# USBTLL register map
Vendor: Texas Instruments
Peripheral module from a debugger description file (folder omap34xx).
Registers are 8-bit, access per field, reset values left out (the file's numbers can be read two ways) unless marked. A register's access mark holds for its fields unless they carry their own. Offsets are as the file gives them; lines under a group give offsets from that group; [hi:lo] are bit positions; {n}, {i} and the like mark numbered series; 'fields as' and 'values as' point back to an identical list; <NAME> marks a mode.

## USBTLL
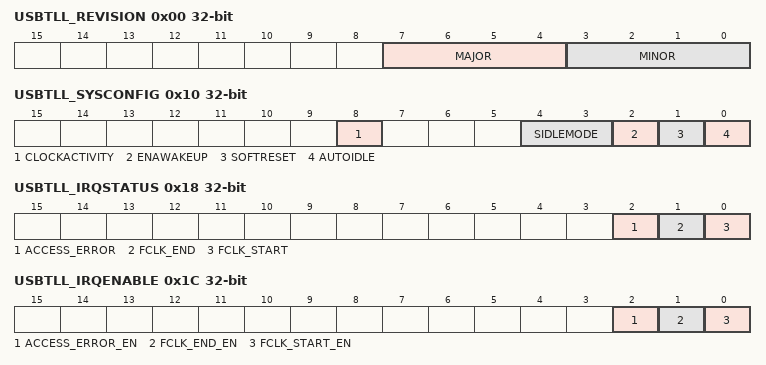
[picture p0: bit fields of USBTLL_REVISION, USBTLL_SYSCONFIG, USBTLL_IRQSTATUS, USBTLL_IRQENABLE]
0x00 USBTLL_REVISION 32-bit ro — Standard revision number, BCD encoded
  [7:4] MAJOR — Major revision number
  [3:0] MINOR — Minor revision number
0x10 USBTLL_SYSCONFIG 32-bit — Standard system configuration register
  [8] CLOCKACTIVITY rw — Enable autogating of L3 interconnect-derived internal clocks while module is idle.
    0=L3 interconnect-derived internal clocks OFF during idle; 1=L3 interconnect-derived internal clocks ON during idle
  [4:3] SIDLEMODE rw — Slave interface power management control. Idle Req/ack control
    0=Force-Idle mode. Sidleack asserted after Idlereq assertion; 1=No-idle mode. Sidleack never asserted.; 2=Smart-idle mode. Sidleack asserted after Idlereq assertion when no more activity on the USB.
  [2] ENAWAKEUP rw — Asynchronous wakeup generation control (Swakeup)
    0=Wakeup generation disabled; 1=Wakeup generation enabled
  [1] SOFTRESET wo — Module software reset
    0=No effect; 1=Starts softreset sequence
  [0] AUTOIDLE rw — Internal autogating control
    0=Clock always running; 1=When no activity on L3 interconnect, clock is cut off
0x14 USBTLL_SYSSTATUS 32-bit ro — Standard system status register
  [0] RESETDONE — Indicates when the module has entirely come out of reset
    0=Reset is ongoing; 1=Reset is done
0x18 USBTLL_IRQSTATUS 32-bit — Standard IRQ status vector. Write 1 to clear a bit.
  [all] fields
    0=No event pending; 1=Event pending
  [2] ACCESS_ERROR rw — Access error to ULPI register over L3 interconnect: USB clock must run for that type of access to succeed.
  [1] FCLK_END rw — Functional clock is no longer requested for USB clockingWhen TLL_SHARED_CONF[1] FCLK_REQ=0 and TLL_SHARED_CONF[0] FCLK_IS_ON=1, IRQ is generated to request the clock to be switched OFF and FCLK_END is set to 1.
  [0] FCLK_START rw — Functional clock is requested for USB clockingWhen TLL_SHARED_CONF[1] FCLK_REQ=1 and TLL_SHARED_CONF[0] FCLK_IS_ON=0, IRQ is generated to request the clock to be switched ON and FCLK_START is set to 1.
0x1C USBTLL_IRQENABLE 32-bit — Standard IRQ enable vector
  [all] fields
    0=IRQ event is masked; 1=IRQ event is enabled
  [2] ACCESS_ERROR_EN rw — Enable IRQ generation upon access error to ULPI register over L3 interconnect
  [1] FCLK_END_EN rw — IRQ event mask for FCLK_END interrupt (seeUSBTLL_IRQSTATUS[1])
  [0] FCLK_START_EN rw — IRQ event mask for FCLK_START interrupt (seeUSBTLL_IRQSTATUS[0])
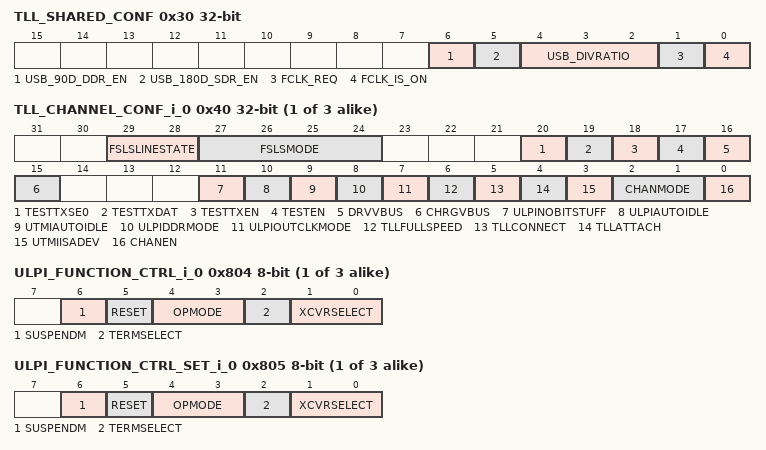
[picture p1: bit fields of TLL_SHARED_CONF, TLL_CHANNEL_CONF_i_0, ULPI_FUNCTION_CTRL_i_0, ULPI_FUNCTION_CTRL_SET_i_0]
0x30 TLL_SHARED_CONF 32-bit — Common control register for all TLL channels
  [6] USB_90D_DDR_EN rw — Software enable/disable of the 90-degree phase shift scheme on output DDR data, when implemented. Read-only, always-0 when HDL generic ULPI_90DEG4DDR = 0.
    0=ULPI DDR output DATA aligned with CLK; 1=ULPI DDR output DATA delayed by 90 degree wrt CLK
  [5] USB_180D_SDR_EN rw — Software enable/disable of the 180-degree phase shift scheme on output SDR data, when implemented. Read-only, always-0 when HDL generic ULPI_180DEG4SDR = 0
    0=ULPI SDR output DATA aligned with CLK; 1=ULPI SDR output DATA delayed by 180 degree wrt CLK
  [4:2] USB_DIVRATIO rw — (Log2 of) division ratio from functional clock to USB (UTMI/ULPI) clock
    0=Div ratio is 2**0 = 1 : Bypass; 1=Div ratio is 2**1 = 2; 2=Div ratio is 2**2 = 4; 3=Div ratio is 2**3 = 8; 4=Div ratio is 2**4 = 16; 5=Div ratio is 2**5 = 32; 6=Div ratio is 2**6 = 64; 7=Div ratio is 2**7 = 128
  [1] FCLK_REQ ro — Functional clock request, ORed from all channels depending on their respective USB bus state.Combined with the Fclk_is_on status to generate fclk_start/end IRQs.
    0=Func clock input is not requested by TLL; 1=Func clock input is requested by TLL
  [0] FCLK_IS_ON rw — Status of the functional clock input, provided by the system to the TLL module. The TLL module will only use that clock if the current status indicated that it is ready.Combined with the Fclk_request to generate fclk_start/end IRQs.
    0=Functional clock input is not guaranteed ON (can actually be ON, OFF, or unstable); 1=Functional clock input is guaranteed ON and stable
{0x40+4i} TLL_CHANNEL_CONF_i_{i} 32-bit (i=0..2) — Control and Status register for channel I.
  [29:28] FSLSLINESTATE ro — Line state for Full/Low speed serial modesBit1 = D–/ Bit0 = D+
    0=Single-ended 0; 1=Full-Speed J = differential 1; 2=Full-Speed K = differential 0; 3=Single-ended 1 (illegal in USB)
  [27:24] FSLSMODE rw — Multiple-mode serial interface's mode select. Only when main channel mode is serial. No effect in other main modes.
    0='6pin' unidirectional PHY i/f mode. TX encoding is Dat/Se0 (default); 1='6-pin' unidirectional PHY i/f mode. TX encoding is Dp/Dm; 2='3-pin' bidirectional PHY i/f mode; 3='4-pin' bidirectional PHY i/f mode; 4='6pin' unidirectional TLL mode. TX encoding is Dat/Se0; 5='6pin' unidirectional TLL mode. TX encoding is Dp/Dm; 6='3-pin' bidirectional TLL mode; 7='4-pin' bidirectional TLL mode; 10='2-pin' bidirectional TLL mode. Encoding is Dat/Se0; 11='2-pin' bidirectional TLL mode. Encoding is Dp/Dm
  [20] TESTTXSE0 rw — Force-Se0 transmit override value for serial mode testDon't care if TestEn = 0 (functional mode) or = TestTxen = 1 (tx = hiz)
    0=Drive differential value on TX according to TestTXDat; 1=Drive SE0 on TX
  [19] TESTTXDAT rw — Differential data transmit override value for serial mode testDon't care if TestEn = 0 (functional mode) or = TestTxen = 1 (tx = hiz) or TestSe0 = 1 (tx = se0)
    0=Drive full-speed K = differential 0; 1=Drive full-speed J = differential 1
  [18] TESTTXEN rw — Differential data transmit override value for serial mode testDon't care if TestEn = 0 (functional mode)
    0=Drive TX according to TestTXDat/Se0; 1=Drive TX Hiz (no drive: Pullups determine line state)
  [17] TESTEN rw — Enable manual test override for serial mode TX path (from local controller's UTMI port)
    0=No override. TX is from local link controller; 1=Override enabled
  [16] DRVVBUS rw — VBUS-drive for ChanMode = serial* In TLL config, write 1 to emulate serial-side VBUS drive* In PHY config, write 1 to report 'VBUS valid' status (of actual VBUS) to UTMI controller
    0=VBUS not driven; 1=VBUS driven to 5V
  [15] CHRGVBUS rw — VBUS-drive for ChanMode = serial* In TLL config, write 1 to emulate serial-side VBUS charge/pullup (OTG)* In PHY config, write 1 to reports 'session valid' status (of actual VBUS) to UTMI controller
    0=VBUS not charged, session not valid; 1=VBUS charged, session valid
  [11] ULPINOBITSTUFF rw — Disable bitstuff emulation in ULPI TLL for ULPI ChanMode
    0=Bitstuff enabled, following USB standard; 1=No bitstuff or associated delays (non-standard)
  [10] ULPIAUTOIDLE rw — For ChanMode = ULPI TLL only. Allow the ULPI output clock to be stopped when ULPI goes into asynchronous mode (low-power, 3-pin serial, 6-pin serial). No effect in ULPI input clock mode.
    0=ULPI output clock always-on; 1=ULPI output clock stops during asynchronous ULPI modes
  [9] UTMIAUTOIDLE rw — For ChanMode = ULPI TLL only. Allow the UTMI clock (output) to be stopped when UTMII goes to suspended mode (suspendm = 0)
    0=UTMI clock output always on; 1=UTMI clock output gated upon suspend
  [8] ULPIDDRMODE rw — Select single/double data rate (SDR/DDR) mode for ULPI TLLReset value depends on hardware generics ULPI_SDR/DDR_MODE.
    0=SDR mode (8 data bit/12 pin); 1=DDR mode (4 data bit/8 pin)
  [7] ULPIOUTCLKMODE rw — ULPI clocking mode select for ULPI TLL ChanMode
    0=ULPI clock provided by LINK (that is, off-chip). ULPI clock is input; 1=ULPI clock provided by PHY side (that is, TLL, from functional clock). ULPI clock is output
  [6] TLLFULLSPEED rw — Sets PHY speed emulation in TLL (full/slow), which determines the line to pull up upon connect. The two connect source controls are: Input m(N)_tllpuen, register field TllConnect.
    0=Connect is Low-speed: D– pullup; 1=Connect is Full-Speed: D+ pullup
  [5] TLLCONNECT rw — Emulation of Full/Low-Speed connect (that is, D+ resp D– pullup) for serial TLL modes. Speed is determined by field TllSpeed.
    0=Unconnected; 1=Connected
  [4] TLLATTACH rw — Emulates cable attach/detach for all serial TLL modes:* ChanMode = serial, in TLL mode (FsLsMode)* ChanMode = ULPI, in serial mode (6pin/3pin TLL)
    0=Cable detach emulated on serial TLL; 1=Cable attach emulated on serial TLL
  [3] UTMIISADEV rw — Select the cable end 'seen' by UTMI side of TLL, that is, the emulated USB cable's orientation.Note that host must always be on A side, Peripheral on B side.Reset value depends on generic DEFUTMIISHOST.
    0=UTMI side is peripheral, ULPI side is host; 1=UTMI side is host, ULPI side is peripheral
  [2:1] CHANMODE rw — Main channel mode selection
    0=UTMI-to-ULPI TLL mode (HS capable): To ULPI controller; 1=UTMI-to-serial (FS/LS) mode: To serial controller (TLL) or serial PHY; 2=Transparent UTMI mode: To UTMI PHY; 3=No mode selected
  [0] CHANEN rw — Active-high channel enable. A disabled channel is unclocked and kept under reset.
    0=Channel #N disabled; 1=Channel #N enabled
{0x800+0x100*i} ULPI_VENDOR_ID_LO_i_{i} ro (i=0..2) — Lower byte of USB-IF-supplied vendor ID Value is set for all channels by HDL generic ULPI_VENDORID Default is Texas-Instruments Vendor ID = 0x0451
  [7:0] VENDOR_ID_LO
{0x801+0x100*i} ULPI_VENDOR_ID_HI_i_{i} ro (i=0..2) — Upper byte of USB-IF-supplied 16-bit vendor ID Value is set for all channels by HDL generic ULPI_VENDORID Default is Texas-Instruments Vendor ID = 0x0451
  [7:0] VENDOR_ID_HI
{0x802+0x100*i} ULPI_PRODUCT_ID_LO_i_{i} ro (i=0..2) — Lower byte of vendor-chosen 16-bit product ID Value is set for all channels by HDL generic ULPI_PRODUCTID
  [7:0] PRODUCT_ID_LO
{0x803+0x100*i} ULPI_PRODUCT_ID_HI_i_{i} ro (i=0..2) — Upper byte of vendor-chosen 16-bit product ID Value is set for all channels by HDL generic ULPI_PRODUCTID
  [7:0] PRODUCT_ID_HI
{0x804+0x100*i} ULPI_FUNCTION_CTRL_i_{i} (i=0..2) — Controls UTMI function settings of the PHY. Read/Write address.
  [6] SUSPENDM rw — Active low PHY suspend: Puts the ULPI bus in Low Power Mode. Automatically set back to 1 upon Low Power Mode exit.
    0=PHY is in low-power mode; 1=PHY is not in low-power mode
  [5] RESET rw — Active high UTMI transceiver reset. Autocleared.Does not reset the ULPI interface or ULPI register set.
    0=No ongoing reset/ no action; 1=Ongoing reset/apply reset
  [4:3] OPMODE rw — Select the required bit encoding style during transmit
    0=Normal operation; 1=Non-driving; 2=Disable bit-stuff and NRZI encoding
  [2] TERMSELECT rw — Controls the internal 1.5Kohms pull-up resistor and 45ohms HS terminations. Control over bus resistors changes depending on XcvrSelect, OpMode, DpPulldown and DmPulldown.
    0=HS termination enabled (other conditions); 1=FS termination enabled (other conditions)
  [1:0] XCVRSELECT rw — Select the required transceiver speed.
    0=Enable HS transceiver; 1=Enable FS transceiver; 2=Enable LS transceiver; 3=Enable FS transceiver for LS packets (automatic FS preamble pre-pending)
{0x805+0x100*i} ULPI_FUNCTION_CTRL_SET_i_{i} (i=0..2) — Controls UTMI function settings of the PHY. Read/set address (write 1 to a bit to set it to 1; writing 0 has no effect on bit value). See fields description at the read/write address of the same register.
  [6] SUSPENDM rw — Active low PHY suspend: Puts the ULPI bus in Low Power Mode. Automatically set back to 1 upon Low Power Mode exit.
    0=SUSPENDM_0_w (No effect on bit value); 1=SUSPENDM_1_w (Set the bit to 1.)
  [5] RESET rw — Active high UTMI transceiver reset. Autocleared.Does not reset the ULPI interface or ULPI register set.
    0=RESET_0_w (No effect on bit value); 1=RESET_1_w (Set the bit to 1.)
  [4:3] OPMODE rw — Select the required bit encoding style during transmit
    0=OPMODE_0_w (No effect on bit value); 1=OPMODE_1_w (Set the bit to 1.)
  [2] TERMSELECT rw — Controls the internal 1.5Kohms pull-up resistor and 45ohms HS terminations. Control over bus resistors changes depending on XcvrSelect, OpMode, DpPulldown and DmPulldown.
    0=TERMSELECT_0_w (No effect on bit value); 1=TERMSELECT_1_w (Set the bit to 1.)
  [1:0] XCVRSELECT rw — Select the required transceiver speed.
    0=XCVRSELECT_0_w (No effect on bit value); 1=XCVRSELECT_1_w (Set the bit to 1.)
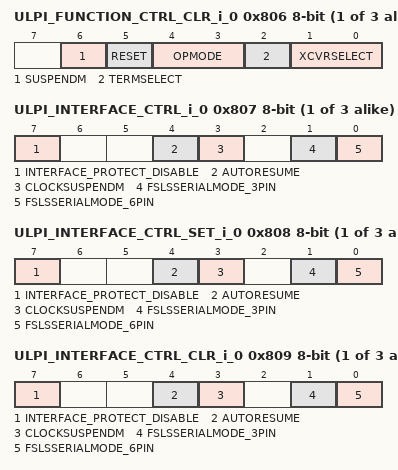
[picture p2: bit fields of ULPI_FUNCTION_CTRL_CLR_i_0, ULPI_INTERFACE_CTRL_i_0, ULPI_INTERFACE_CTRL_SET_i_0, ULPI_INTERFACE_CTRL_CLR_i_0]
{0x806+0x100*i} ULPI_FUNCTION_CTRL_CLR_i_{i} (i=0..2) — Controls UTMI function settings of the PHY. Read/clear address (write 1 to a bit to clear it to 0, writing 0 has no effect on bit value). See fields description at the read/write address of the same register.
  [6] SUSPENDM rw — Active low PHY suspend: Puts the ULPI bus in Low Power Mode. Automatically set back to 1 upon Low Power Mode exit.
    0=SUSPENDM_0_w (No effect on bit value); 1=SUSPENDM_1_w (Clear the bit to 0)
  [5] RESET rw — Active high UTMI transceiver reset. Autocleared.Does not reset the ULPI interface or ULPI register set.
    0=RESET_0_w (No effect on bit value); 1=RESET_1_w (Clear the bit to 0)
  [4:3] OPMODE rw — Select the required bit encoding style during transmit
    0=OPMODE_0_w (No effect on bit value); 1=OPMODE_1_w (Clear the bit to 0)
  [2] TERMSELECT rw — Controls the internal 1.5Kohms pull-up resistor and 45ohms HS terminations. Control over bus resistors changes depending on XcvrSelect, OpMode, DpPulldown and DmPulldown.
    0=TERMSELECT_0_w (No effect on bit value); 1=TERMSELECT_1_w (Clear the bit to 0)
  [1:0] XCVRSELECT rw — Select the required transceiver speed.
    0=XCVRSELECT_0_w (No effect on bit value); 1=XCVRSELECT_1_w (Clear the bit to 0)
{0x807+0x100*i} ULPI_INTERFACE_CTRL_i_{i} (i=0..2) — Enables alternative interfaces and PHY features. Read/Write address.
  [7] INTERFACE_PROTECT_DISABLE rw — Controls circuitry built into the PHY for protecting the ULPI interface when the link 3-states stp and data.
    0=Enables the interface protect circuit; 1=Disables the interface protect circuit
  [4] AUTORESUME rw — Enables the PHY to automatically drive resume signaling. On by default.
    0=AutoResume disabled; 1=AutoResume enabled
  [3] CLOCKSUSPENDM rw — Active low clock suspend for serial modes (6pin/3-pin).
    0=ULPI clock will stop during serial modes; 1=ULPI clock will run during serial modes
  [1] FSLSSERIALMODE_3PIN rw — Sets the ULPI interface to 3-pin (FS/LS only) Serial Mode. Autocleared when serial mode is exited.
    0=ULPI is not in 3-pin mode; 1=ULPI in 3-pin serial mode
  [0] FSLSSERIALMODE_6PIN rw — Sets the ULPI interface to 6-pin (FS/LS only) Serial Mode. Autocleared when serial mode is exited.
    0=ULPI is not in 6-pin mode; 1=ULPI in 6-pin serial mode
{0x808+0x100*i} ULPI_INTERFACE_CTRL_SET_i_{i} (i=0..2) — Enables alternative interfaces and PHY features. Read/set address (write 1 to a bit to set it to 1; writing 0 has no effect on bit value). See fields description at the read/write address of the same register.
  [7] INTERFACE_PROTECT_DISABLE rw — Controls circuitry built into the PHY for protecting the ULPI interface when the link 3-states stp and data.
    0=INTERFACE_PROTECT_DISABLE_0_w (No effect on bit value); 1=INTERFACE_PROTECT_DISABLE_1_w (Set the bit to 1.)
  [4] AUTORESUME rw — Enables the PHY to automatically drive resume signaling. On by default.
    0=AUTORESUME_0_w (No effect on bit value); 1=AUTORESUME_1_w (Set the bit to 1.)
  [3] CLOCKSUSPENDM rw — Active low clock suspend for serial modes (6pin/3-pin).
    0=CLOCKSUSPENDM_0_w (No effect on bit value); 1=CLOCKSUSPENDM_1_w (Set the bit to 1.)
  [1] FSLSSERIALMODE_3PIN rw — Sets the ULPI interface to 3-pin (FS/LS only) Serial Mode. Autocleared when serial mode is exited.
    0=FSLSSERIALMODE_3PIN_0_w (No effect on bit value); 1=FSLSSERIALMODE_3PIN_1_w (Set the bit to 1.)
  [0] FSLSSERIALMODE_6PIN rw — Sets the ULPI interface to 6-pin (FS/LS only) Serial Mode. Autocleared when serial mode is exited.
    0=FSLSSERIALMODE_6PIN_0_w (No effect on bit value); 1=FSLSSERIALMODE_6PIN_1_w (Set the bit to 1.)
{0x809+0x100*i} ULPI_INTERFACE_CTRL_CLR_i_{i} (i=0..2) — Enables alternative interfaces and PHY features. Read/clear address (write 1 to a bit to clear it to 0, writing 0 has no effect on bit value). See fields description at the read/write address of the same register.
  [7] INTERFACE_PROTECT_DISABLE rw — Controls circuitry built into the PHY for protecting the ULPI interface when the link 3-states stp and data.
    0=INTERFACE_PROTECT_DISABLE_0_w (No effect on bit value); 1=INTERFACE_PROTECT_DISABLE_1_w (Clear the bit to 0)
  [4] AUTORESUME rw — Enables the PHY to automatically drive resume signaling. On by default.
    0=AUTORESUME_0_w (No effect on bit value); 1=AUTORESUME_1_w (Clear the bit to 0)
  [3] CLOCKSUSPENDM rw — Active low clock suspend for serial modes (6pin/3-pin).
    0=CLOCKSUSPENDM_0_w (No effect on bit value); 1=CLOCKSUSPENDM_1_w (Clear the bit to 0)
  [1] FSLSSERIALMODE_3PIN rw — Sets the ULPI interface to 3-pin (FS/LS only) Serial Mode. Autocleared when serial mode is exited.
    0=FSLSSERIALMODE_3PIN_0_w (No effect on bit value); 1=FSLSSERIALMODE_3PIN_1_w (Clear the bit to 0)
  [0] FSLSSERIALMODE_6PIN rw — Sets the ULPI interface to 6-pin (FS/LS only) Serial Mode. Autocleared when serial mode is exited.
    0=FSLSSERIALMODE_6PIN_0_w (No effect on bit value); 1=FSLSSERIALMODE_6PIN_1_w (Clear the bit to 0)
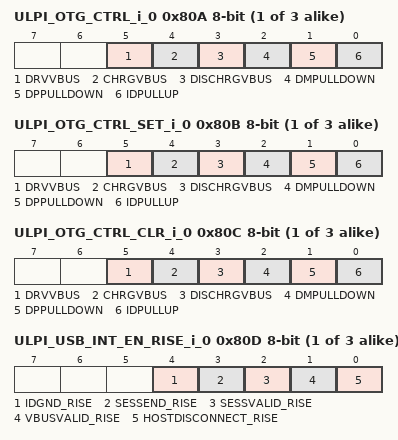
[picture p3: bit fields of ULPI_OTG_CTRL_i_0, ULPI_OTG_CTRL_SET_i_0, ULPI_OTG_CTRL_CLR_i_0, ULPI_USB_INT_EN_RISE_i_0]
{0x80A+0x100*i} ULPI_OTG_CTRL_i_{i} (i=0..2) — Controls UTMI+ OTG functions of the PHY. Read/Write address.
  [5] DRVVBUS rw — Drive 5 V on VBUS
    0=No action; 1=Drive VBUS
  [4] CHRGVBUS rw — Charge VBUS through a resistor for VBUS-pulsing SRP.
    0=No action; 1=Charge VBUS
  [3] DISCHRGVBUS rw — Discharge VBUS through a resistor, until the session-end VBUS state is reached.
    0=No action; 1=Discharge VBUS
  [2] DMPULLDOWN rw — Enables the 15kΩ pull-down resistor on D–
    0=Pull-down resistor not connected to D–; 1=Pull-down resistor connected to D–
  [1] DPPULLDOWN rw — Enables the 15kΩ pull-down resistor on D+
    0=Pull-down resistor not connected to D+; 1=Pull-down resistor connected to D+
  [0] IDPULLUP rw — Pull-up to the (OTG) ID line to allow its sampling
    0=Disable sampling of ID line; 1=Enable sampling of ID line
{0x80B+0x100*i} ULPI_OTG_CTRL_SET_i_{i} (i=0..2) — Controls UTMI+ OTG functions of the PHY. Read/set address (write 1 to a bit to set it to 1; writing 0 has no effect on bit value). See fields description at the read/write address of the same register.
  [5] DRVVBUS rw — Drive 5 V on VBUS
    0=DRVVBUS_0_w (No effect on bit value); 1=DRVVBUS_1_w (Set the bit to 1.)
  [4] CHRGVBUS rw — Charge VBUS through a resistor for VBUS-pulsing SRP.
    0=CHRGVBUS_0_w (No effect on bit value); 1=Set the bit to 1
  [3] DISCHRGVBUS rw — Discharge VBUS through a resistor, until the session-end VBUS state is reached.
    0=DISCHRGVBUS_0_w (No effect on bit value); 1=DISCHRGVBUS_1_w (Set the bit to 1.)
  [2] DMPULLDOWN rw — Enables the 15kΩ pull-down resistor on D–
    0=DMPULLDOWN_0_w (No effect on bit value); 1=DMPULLDOWN_1_w (Set the bit to 1.)
  [1] DPPULLDOWN rw — Enables the 15kΩ pull-down resistor on D+
    0=DPPULLDOWN_0_w (No effect on bit value); 1=DPPULLDOWN_1_w (Set the bit to 1.)
  [0] IDPULLUP rw — Pull-up to the (OTG) ID line to allow its sampling
    0=IDPULLUP_0_w (No effect on bit value); 1=IDPULLUP_1_w (Set the bit to 1.)
{0x80C+0x100*i} ULPI_OTG_CTRL_CLR_i_{i} (i=0..2) — Controls UTMI+ OTG functions of the PHY. Read/clear address (write 1 to a bit to clear it to 0, writing 0 has no effect on bit value). See fields description at the read/write address of the same register.
  [5] DRVVBUS rw — Drive 5 V on VBUS
    0=DRVVBUS_0_w (No effect on bit value); 1=DRVVBUS_1_w (Clear the bit to 0)
  [4] CHRGVBUS rw — Charge VBUS through a resistor for VBUS-pulsing SRP.
    0=CHRGVBUS_0_w (No effect on bit value); 1=CHRGVBUS_1_w (Clear the bit to 0)
  [3] DISCHRGVBUS rw — Discharge VBUS through a resistor, until the session-end VBUS state is reached.
    0=DISCHRGVBUS_0_w (No effect on bit value); 1=DISCHRGVBUS_1_w (Clear the bit to 0)
  [2] DMPULLDOWN rw — Enables the 15kΩ pull-down resistor on D–
    0=DMPULLDOWN_0_w (No effect on bit value); 1=DMPULLDOWN_1_w (Clear the bit to 0)
  [1] DPPULLDOWN rw — Enables the 15kΩ pull-down resistor on D+
    0=DPPULLDOWN_0_w (No effect on bit value); 1=DPPULLDOWN_1_w (Clear the bit to 0)
  [0] IDPULLUP rw — Pull-up to the (OTG) ID line to allow its sampling
    0=IDPULLUP_0_w (No effect on bit value); 1=IDPULLUP_1_w (Clear the bit to 0)
{0x80D+0x100*i} ULPI_USB_INT_EN_RISE_i_{i} (i=0..2) — Enables an interrupt event notification when the corresponding status bit changes from low to high. By default, all transitions are enabled. Read/Write address.
  [4] IDGND_RISE rw — Generate an interrupt event notification when IdGnd changes from low to high.Event is automatically masked if IdPullup bit is cleared to 0 and for 50 ms after IdPullup is set to 1.
  [3] SESSEND_RISE rw — Generate an interrupt event notification when SessEnd changes from low to high.
  [2] SESSVALID_RISE rw — Generate an interrupt event notification when SessValid changes from low to high. SessValid is the same as UTMI+ AValid.
  [1] VBUSVALID_RISE rw — Generate an interrupt event notification when VbusValid changes from low to high.
  [0] HOSTDISCONNECT_RISE rw — Generate an interrupt event notification when Hostdisconnect changes from low to high. Applicable only in host mode (DpPulldown and DmPulldown both set to 1b).
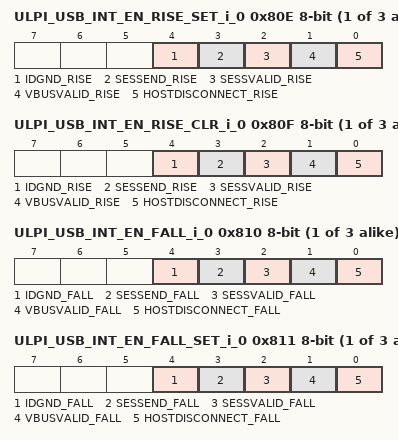
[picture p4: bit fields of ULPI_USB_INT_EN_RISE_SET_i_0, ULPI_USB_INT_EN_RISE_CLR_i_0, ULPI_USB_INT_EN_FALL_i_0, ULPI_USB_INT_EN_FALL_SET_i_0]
{0x80E+0x100*i} ULPI_USB_INT_EN_RISE_SET_i_{i} (i=0..2) — Enables an interrupt event notification when the corresponding status bit changes from low to high. Read/set address (write 1 to a bit to set it to 1; writing 0 has no effect on bit value). See fields description at the read/write address of the same register.
  [4] IDGND_RISE rw — Generate an interrupt event notification when IdGnd changes from low to high.Event is automatically masked if the IdPullup bit is cleared to 0 and for 50 ms after IdPullup is set to 1.Write 0x0: No effect on bit value Write 0x1: Set the bit to 1.
  [3] SESSEND_RISE rw — Generate an interrupt event notification when SessEnd changes from low to high.Write 0x0: No effect on bit value Write 0x1: Set the bit to 1.
  [2] SESSVALID_RISE rw — Generate an interrupt event notification when SessValid changes from low to high. SessValid is the same as UTMI+ AValid.Write 0x0: No effect on bit value Write 0x1: Set the bit to 1.
  [1] VBUSVALID_RISE rw — Generate an interrupt event notification when VbusValid changes from low to high.Write 0x0: No effect on bit value Write 0x1: Set the bit to 1.
  [0] HOSTDISCONNECT_RISE rw — Generate an interrupt event notification when Hostdisconnect changes from low to high. Applicable only in host mode (DpPulldown and DmPulldown both set to 1b).Write 0x0: No effect on bit value Write 0x1: Set the bit to 1.
{0x80F+0x100*i} ULPI_USB_INT_EN_RISE_CLR_i_{i} (i=0..2) — Enables an interrupt event notification when the corresponding status bit changes from low to high. Read/clear address (write 1 to a bit to clear it to 0, writing 0 has no effect on bit value). See fields description at the read/write address of the same register.
  [4] IDGND_RISE rw — Generate an interrupt event notification when IdGnd changes from low to high.Event is automatically masked if the IdPullup bit is cleared to 0 and for 50 ms after IdPullup is set to 1.Write 0x0: No effect on bit value Write 0x1: Clear the bit to 0
  [3] SESSEND_RISE rw — Generate an interrupt event notification when SessEnd changes from low to high.Write 0x0: No effect on bit value Write 0x1: Clear the bit to 0
  [2] SESSVALID_RISE rw — Generate an interrupt event notification when SessValid changes from low to high. SessValid is the same as UTMI+ AValid.Write 0x0: No effect on bit value Write 0x1: Clear the bit to 0
  [1] VBUSVALID_RISE rw — Generate an interrupt event notification when VbusValid changes from low to high.Write 0x0: No effect on bit value Write 0x1: Clear the bit to 0
  [0] HOSTDISCONNECT_RISE rw — Generate an interrupt event notification when Hostdisconnect changes from low to high. Applicable only in host mode (DpPulldown and DmPulldown both set to 1b).Write 0x0: No effect on bit value Write 0x1: Clear the bit to 0
{0x810+0x100*i} ULPI_USB_INT_EN_FALL_i_{i} (i=0..2) — Enables an interrupt event notification when the corresponding status bit changes from high to low. By default, all transitions are enabled. Read/Write address.
  [4] IDGND_FALL rw — Generate an interrupt event notification when IdGnd changes from high to low.Event is automatically masked if IdPullup bit is cleared to 0 and for 50 ms after IdPullup is set to 1.
  [3] SESSEND_FALL rw — Generate an interrupt event notification when SessEnd changes from high to low.
  [2] SESSVALID_FALL rw — Generate an interrupt event notification when SessValid changes from high to low. SessValid is the same as UTMI+ AValid.
  [1] VBUSVALID_FALL rw — Generate an interrupt event notification when VbusValid changes from high to low.
  [0] HOSTDISCONNECT_FALL rw — Generate an interrupt event notification when Hostdisconnect changes from high to low. Applicable only in host mode (DpPulldown and DmPulldown both set to 1b).
{0x811+0x100*i} ULPI_USB_INT_EN_FALL_SET_i_{i} (i=0..2) — Enables an interrupt event notification when the corresponding status bit changes from high to low. Read/set address (write 1 to a bit to set it to 1; writing 0 has no effect on bit value). See fields description at the read/write address of the same register.
  [4] IDGND_FALL rw — Generate an interrupt event notification when IdGnd changes from high to low.Event is automatically masked if the IdPullup bit is cleared to 0 and for 50 ms after IdPullup is set to 1.Write 0x0: No effect on bit value Write 0x1: Set the bit to 1.
  [3] SESSEND_FALL rw — Generate an interrupt event notification when SessEnd changes from high to low.Write 0x0: No effect on bit value Write 0x1: Set the bit to 1.
  [2] SESSVALID_FALL rw — Generate an interrupt event notification when SessValid changes from high to low. SessValid is the same as UTMI+ AValid.Write 0x0: No effect on bit value Write 0x1: Set the bit to 1.
  [1] VBUSVALID_FALL rw — Generate an interrupt event notification when VbusValid changes from high to low.Write 0x0: No effect on bit value Write 0x1: Set the bit to 1.
  [0] HOSTDISCONNECT_FALL rw — Generate an interrupt event notification when Hostdisconnect changes from high to low. Applicable only in host mode (DpPulldown and DmPulldown both set to 1b).Write 0x0: No effect on bit value Write 0x1: Set the bit to 1.
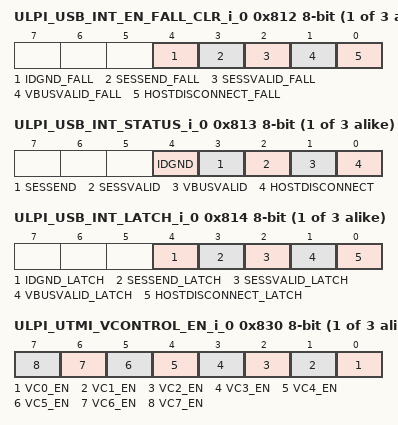
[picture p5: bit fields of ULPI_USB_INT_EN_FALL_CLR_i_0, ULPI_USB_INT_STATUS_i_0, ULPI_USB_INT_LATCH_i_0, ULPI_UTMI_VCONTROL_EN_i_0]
{0x812+0x100*i} ULPI_USB_INT_EN_FALL_CLR_i_{i} (i=0..2) — Enables an interrupt event notification when the corresponding status bit changes from high to low. Read/clear address (write 1 to a bit to clear it to 0, writing 0 has no effect on bit value). See fields description at the read/write address of the same register.
  [4] IDGND_FALL rw — Generate an interrupt event notification when IdGnd changes from high to low.Event is automatically masked if the IdPullup bit is cleared to 0 and for 50 ms after IdPullup is set to 1.Write 0x0: No effect on bit value Write 0x1: Clear the bit to 0
  [3] SESSEND_FALL rw — Generate an interrupt event notification when SessEnd changes from high to low.Write 0x0: No effect on bit value Write 0x1: Clear the bit to 0
  [2] SESSVALID_FALL rw — Generate an interrupt event notification when SessValid changes from high to low. SessValid is the same as UTMI+ AValid.Write 0x0: No effect on bit value Write 0x1: Clear the bit to 0
  [1] VBUSVALID_FALL rw — Generate an interrupt event notification when VbusValid changes from high to low.Write 0x0: No effect on bit value Write 0x1: Clear the bit to 0
  [0] HOSTDISCONNECT_FALL rw — Generate an interrupt event notification when Hostdisconnect changes from high to low. Applicable only in host mode (DpPulldown and DmPulldown both set to 1b).Write 0x0: No effect on bit value Write 0x1: Clear the bit to 0
{0x813+0x100*i} ULPI_USB_INT_STATUS_i_{i} ro (i=0..2) — Indicates the current value of the interrupt source signal.
  [4] IDGND — Value of UTMI+ IdDig output. Undefined unless IdPullup = 1
    0=ID pin is grounded = OTG A = default Host; 1=ID pin is floating = OTG B = default Peripheral
  [3] SESSEND — Current value of UTMI+ SessEnd output.
    0=VBUS is above Session-End threshold; 1=VBUS is below Session-End threshold
  [2] SESSVALID — Current value of UTMI+ SessValid output. SessValid is the same as UTMI+ AValid.
    0=VBUS is below Session-Valid threshold; 1=VBUS is above Session-Valid threshold
  [1] VBUSVALID — Current value of UTMI+ VbusValid output.
    0=VBUS is below Vbus-Valid threshold; 1=VBUS is above Vbus-Valid threshold
  [0] HOSTDISCONNECT — Current value of UTMI+ Hostdisconnect output. Applicable only in host mode. Automatically reset to 0 when Low Power Mode is entered.
    0=Peripheral not disconnected or non-host mode; 1=Peripheral disconnected
{0x814+0x100*i} ULPI_USB_INT_LATCH_i_{i} ro (i=0..2) — Set by unmasked changes on the corresponding status bits to generate the ULPI interrupt. Cleared upon read, and when Low Power Mode, Serial Mode or Carkit Mode are entered.
  [4] IDGND_LATCH — Set to 1 by the PHY when an unmasked event occurs on IdGnd. Cleared when this register is read.
  [3] SESSEND_LATCH — Set to 1 by the PHY when an unmasked event occurs on SessEnd. Cleared when this register is read.
  [2] SESSVALID_LATCH — Set to 1 by the PHY when an unmasked event occurs on SessValid. Cleared when this register is read. SessValid is the same as UTMI+ AValid.
  [1] VBUSVALID_LATCH — Set to 1 by the PHY when an unmasked event occurs on VbusValid. Cleared when this register is read.
  [0] HOSTDISCONNECT_LATCH — Set to 1 by the PHY when an unmasked event occurs on Hostdisconnect. Cleared when this register is read. Applicable only in host mode.
{0x815+0x100*i} ULPI_DEBUG_i_{i} ro (i=0..2) — Indicates the current value of various signals useful for debugging.
  [1:0] LINESTATE — Current state of the USB line: D+ (bit 0) and D– (bit 1).
    0=SE0 (LS/FS), Squelch (HS/Chirp); 1=LS: 'K' State, FS: 'J' State, HS: !Squelch, Chirp: !Squelch & HS_Differential_Receiver_Output; 2=LS: 'J' State, FS: 'K' State, HS: Invalid, Chirp: !Squelch & !HS_Differential_Receiver_Output; 3=SE1 (LS/FS), Invalid (HS/Chirp)
{0x816+0x100*i} ULPI_SCRATCH_REGISTER_i_{i} rw (i=0..2) — Register byte for register access testing purposes. Value has no functional effect on PHY. Read/Write address.
  [7:0] SCRATCH — Scratch data.
{0x817+0x100*i} ULPI_SCRATCH_REGISTER_SET_i_{i} rw (i=0..2) — Register byte for register access testing purposes. Value has no functional effect on PHY. Read/set address (write 1 to a bit to set it to 1; writing 0 has no effect on bit value). See fields description at the read/write address of the same register.
  [7:0] SCRATCH — Scratch datawrite 1 to a bit to set it to 1writing 0 has no effect on bit value
{0x818+0x100*i} ULPI_SCRATCH_REGISTER_CLR_i_{i} rw (i=0..2) — Register byte for register access testing purposes. Value has no functional effect on PHY. Read/clear address (write 1 to a bit to clear it to 0, writing 0 has no effect on bit value). See fields description at the read/write address of the same register.
  [7:0] SCRATCH — Scratch datawrite 1 to a bit to clear it to 0writing 0 has no effect on bit value
{0x82F+0x100*i} ULPI_EXTENDED_SET_ACCESS_i_{i} rw (i=0..2) — This address is used to access the extended register set, that is, addresses above 0x40.
  [7:0] SET_ACCESS — This bitfield is used to access the extended register set, that is, addresses above 0x40.
{0x830+0x100*i} ULPI_UTMI_VCONTROL_EN_i_{i} rw (i=0..2) — Part of non-standard UTMI-to-ULPI mailbox system, implemented if HDL generic VCS_MAILBOX bit is 1 Enables an interrupt notification when the corresponding vcontrol_status bit changes. Read/Write address. Lowest VCS_CTRL_WIDTH (HDL generic) bits are implemented, others are always-0, read-only. (UTMI standard is 4-bit).
  [n] VC{n}_EN (n=0..7) — Enable alt_int assertion upon vcontrol_status bit change
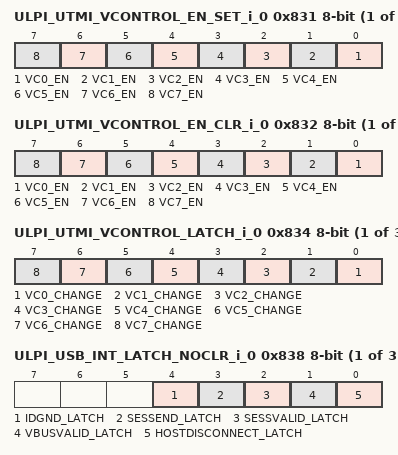
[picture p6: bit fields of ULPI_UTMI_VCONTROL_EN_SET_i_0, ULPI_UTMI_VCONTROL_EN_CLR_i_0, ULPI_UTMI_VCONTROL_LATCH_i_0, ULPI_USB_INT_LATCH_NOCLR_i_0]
{0x831+0x100*i} ULPI_UTMI_VCONTROL_EN_SET_i_{i} rw (i=0..2) — Part of non-standard UTMI-to-ULPI mailbox system, implemented if HDL generic VCS_MAILBOX bit is 1 Enables an interrupt notification when the corresponding vcontrol_status bit changes. Read/set address (write 1 to a bit to set it to 1; writing 0 has no effect on bit value). See fields description at the read/write address of the same register.
  [n] VC{n}_EN (n=0..7) — Enable alt_int assertion upon vcontrol_status bit changeWrite 0x0: No effect on bit value Write 0x1: Set the bit to 1.
{0x832+0x100*i} ULPI_UTMI_VCONTROL_EN_CLR_i_{i} rw (i=0..2) — Part of non-standard UTMI-to-ULPI mailbox system, implemented if HDL generic VCS_MAILBOX bit is 1 Enables an interrupt notification when the corresponding vcontrol_status bit changes. Read/clear address (write 1 to a bit to clear it to 0, writing 0 has no effect on bit value). See fields description at the read/write address of the same register.
  [n] VC{n}_EN (n=0..7) — Enable alt_int assertion upon vcontrol_status bit changeWrite 0x0: No effect on bit value Write 0x1: Clear the bit to 0
{0x833+0x100*i} ULPI_UTMI_VCONTROL_STATUS_i_{i} rw (i=0..2) — Part of non-standard UTMI-to-ULPI mailbox system, implemented if HDL generic VCS_MAILBOX bit is 1 UTMI-standard Vcontrol vector byte is sent by the UTMI controller (other side of TLL) to its PHY (emulated here by the TLL). Alternatively, data can be also written directly into the register. Can contain any user-defined data. Vcontrol bit changes can be used to assert the ULPI ALT interrupt. Lowest VCS_CTRL_WIDTH (HDL generic) bits are implemented, others are always-0, read-only. (UTMI standard is 4-bit).
  [7:0] VC — User-defined UTMI Control data byte
{0x834+0x100*i} ULPI_UTMI_VCONTROL_LATCH_i_{i} ro (i=0..2) — Part of non-standard UTMI-to-ULPI mailbox system, implemented if HDL generic VCS_MAILBOX bit is 1 Set by unmasked changes on the corresponding vcontrol_status bits to generate the ULPI ALT interrupt. Cleared upon read, and when Low Power Mode, Serial Mode or Carkit Mode are entered. Lowest VCS_CTRL_WIDTH (HDL generic) bits are implemented, others are always-0, read-only. (UTMI standard is 4-bit).
  [n] VC{n}_CHANGE (n=0..7) — Unmasked change on vcontrol_status bit
{0x835+0x100*i} ULPI_UTMI_VSTATUS_i_{i} rw (i=0..2) — Part of non-standard UTMI-to-ULPI mailbox system, implemented if HDL generic VCS_MAILBOX bit is 1 UTMI-standard Vstatus vector byte is sent by the PHY (emulated here by the TLL) to the UTMI controller (other side of TLL): Information written into this register will go directly to the UTMI controller, and can contain any user-defined data. Read/Write address. Lowest VCS_STAT_WIDTH (HDL generic) bits are implemented, others are always-0, read-only. (UTMI standard is 8-bit).
  [7:0] VS — User-defined UTMI Status data byte
{0x836+0x100*i} ULPI_UTMI_VSTATUS_SET_i_{i} rw (i=0..2) — Part of non-standard UTMI-to-ULPI mailbox system, implemented if HDL generic VCS_MAILBOX bit is 1 UTMI-standard Vstatus vector byte is sent by the PHY (emulated here by the TLL) to the UTMI controller (other side of TLL): Information written into this register will go directly to the UTMI controller, and can contain any user-defined data. Read/set address (write 1 to a bit to set it to 1; writing 0 has no effect on bit value). See fields description at the read/write address of the same register.
  [7:0] VS — User-defined UTMI status data byteWrite 0x0: No effect on bit value Write 0x1: Set the bit to 1.
{0x837+0x100*i} ULPI_UTMI_VSTATUS_CLR_i_{i} rw (i=0..2) — Part of non-standard UTMI-to-ULPI mailbox system, implemented if HDL generic VCS_MAILBOX bit is 1 UTMI-standard Vstatus vector byte is sent by the PHY (emulated here by the TLL) to the UTMI controller (other side of TLL): Information written into this register will go directly to the UTMI controller, and can contain any user-defined data. Read/clear address (write 1 to a bit to clear it to 0, writing 0 has no effect on bit value). See fields description at the read/write address of the same register.
  [7:0] VS — User-defined UTMI status data byteWrite 0x0: No effect on bit value Write 0x1: Clear the bit to 0
{0x838+0x100*i} ULPI_USB_INT_LATCH_NOCLR_i_{i} ro (i=0..2) — Set by unmasked changes on the corresponding status bits to generate the ULPI interrupt. Debug, non-standard address to the standard register: Register is not cleared on read. See fields description at the 'clear-on-read' address of the same register.
  [4] IDGND_LATCH — Set to 1 by the PHY when an unmasked event occurs on IdGnd.
  [3] SESSEND_LATCH — Set to 1 by the PHY when an unmasked event occurs on SessEnd.
  [2] SESSVALID_LATCH — Set to 1 by the PHY when an unmasked event occurs on SessValid. SessValid is the same as UTMI+ AValid.
  [1] VBUSVALID_LATCH — Set to 1 by the PHY when an unmasked event occurs on VbusValid.
  [0] HOSTDISCONNECT_LATCH — Set to 1 by the PHY when an unmasked event occurs on Hostdisconnect. Applicable only in host mode.
{0x83B+0x100*i} ULPI_VENDOR_INT_EN_i_{i} (i=0..2) — Vendor-specific interrupt enables (mask) for miscellaneous ULPI alt_int events. Read/Write address.
  [0] P2P_EN rw — Enable PHY-to-PHY ULPI wakeup upon inactive UTMI suspendm.
    0=PHY-to-PHY wakeup enabled; 1=PHY-to-PHY wakeup enabled
{0x83C+0x100*i} ULPI_VENDOR_INT_EN_SET_i_{i} (i=0..2) — Vendor-specific interrupt enable bit (mask) for miscellaneous ULPI alt_int events. Read/set address (write 1 to a bit to set it to 1; writing 0 has no effect on bit value). See fields description at the read/write address of the same register.
  [0] P2P_EN rw — Enable PHY-to-PHY ULPI wakeup upon inactive UTMI suspendm.
    0=P2P_EN_0_w (No effect on bit value); 1=P2P_EN_1_w (Set the bit to 1.)
{0x83D+0x100*i} ULPI_VENDOR_INT_EN_CLR_i_{i} (i=0..2) — Vendor-specific interrupt enables (mask) for miscellaneous ULPI alt_int events. Read/clear address (write 1 to a bit to clear it to 0, writing 0 has no effect on bit value). See fields description at the read/write address of the same register.
  [0] P2P_EN rw — Enable PHY-to-PHY ULPI wakeup upon inactive UTMI suspendm.
    0=P2P_EN_0_w (No effect on bit value); 1=P2P_EN_1_w (Clear the bit to 0)
{0x83E+0x100*i} ULPI_VENDOR_INT_STATUS_i_{i} ro (i=0..2) — Vendor-specific interrupt sources for miscellaneous ULPI alt_int events.
  [0] UTMI_SUSPENDM — UTMI suspendm status (active-low), source of TLL PHY-to-PHY wakeup interrupt.
    0=UTMI interface is suspended; 1=UTMI interface is active (not suspended)
{0x83F+0x100*i} ULPI_VENDOR_INT_LATCH_i_{i} ro (i=0..2) — Vendor-specific interrupt latches for miscellaneous ULPI alt_int events. Cleared upon read, and when Low Power Mode, Serial Mode or Carkit Mode are entered.
  [0] P2P_LATCH — PHY-to-PHY ULPI wakeup event latch. Set when ULPI is in low-power mode (suspendm = 0) and UTMI is active (suspendm = 1).
    0=No PHY-to-PHY wakeup event latched; 1=PHY-to-PHY wakeup event was latched, ALT interrupt active
